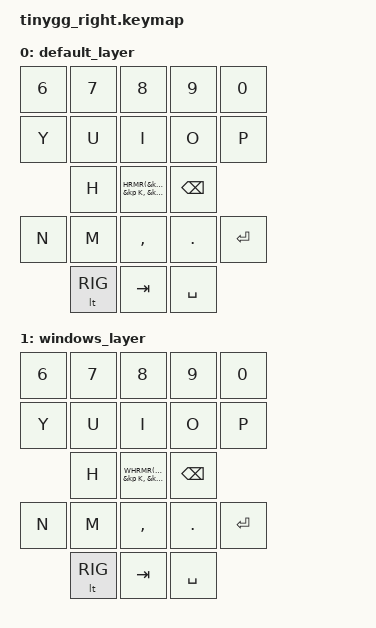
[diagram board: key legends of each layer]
// SPDX-License-Identifier: MIT

#include <behaviors.dtsi>
#include <dt-bindings/zmk/keys.h>
#include <dt-bindings/zmk/bt.h>
#include <dt-bindings/zmk/outputs.h>

// Home row mods macro
#define HRML(k2,k3,k4) &ht LALT k2  &ht LCTRL k3  &ht LGUI k4
#define HRMR(k1,k2,k3) &ht RGUI k1  &ht RCTRL k2  &ht RALT k3

#define MAC 0
#define WIN 1
#define RIG 2
#define LEF 3
#define TRI 4

/ {
    keymap {
        compatible = "zmk,keymap";
        default_layer {
            bindings = <
        // Right half
                  &kp N6     &kp N7     &kp N8     &kp N9     &kp N0
            &kp Y      &kp U      &kp I      &kp O      &kp P
            &kp H      HRMR(&kp J, &kp K, &kp L)   &kp BSPC
            &kp N      &kp M      &kp COMMA  &kp DOT    &kp ENTER
            &lt RIG &kp TAB  &kp SPACE
            >;
        };

        windows_layer {
            bindings = <
        // Right half
                  &kp N6     &kp N7     &kp N8     &kp N9     &kp N0
            &kp Y      &kp U      &kp I      &kp O      &kp P
            &kp H      WHRMR(&kp J, &kp K, &kp L)   &kp BSPC
            &kp N      &kp M      &kp COMMA  &kp DOT    &kp ENTER
            &lt RIG &kp TAB  &kp SPACE
            >;
        };

        // Additional layers as needed
    };
};
